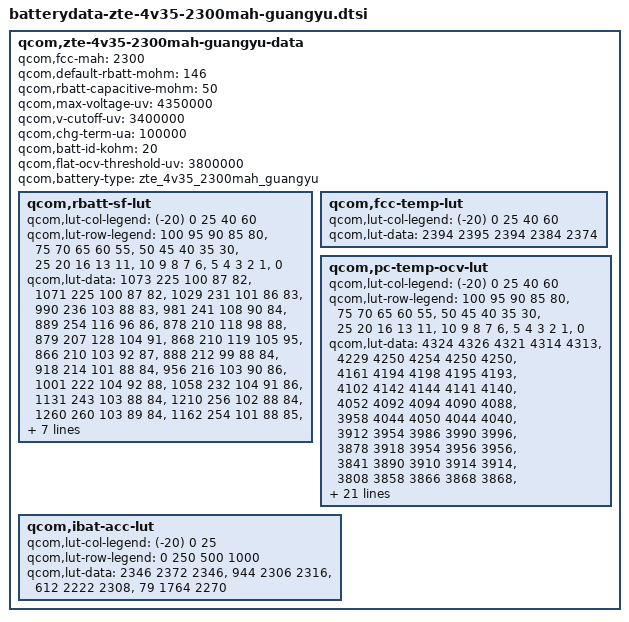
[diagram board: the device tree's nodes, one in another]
/* Copyright (c) 2014, The Linux Foundation. All rights reserved.
 *
 * This program is free software; you can redistribute it and/or modify
 * it under the terms of the GNU General Public License version 2 and
 * only version 2 as published by the Free Software Foundation.
 *
 * This program is distributed in the hope that it will be useful,
 * but WITHOUT ANY WARRANTY; without even the implied warranty of
 * MERCHANTABILITY or FITNESS FOR A PARTICULAR PURPOSE.  See the
 * GNU General Public License for more details.
 */
 qcom,zte-4v35-2300mah-guangyu-data {
	qcom,fcc-mah = <2300>;
	qcom,default-rbatt-mohm = <146>;
	qcom,rbatt-capacitive-mohm = <50>;
	qcom,max-voltage-uv = <4350000>;
	qcom,v-cutoff-uv = <3400000>;
	qcom,chg-term-ua = <100000>;
	qcom,batt-id-kohm = <20>;
	qcom,flat-ocv-threshold-uv = <3800000>;
	qcom,battery-type = "zte_4v35_2300mah_guangyu";

	qcom,rbatt-sf-lut {
		qcom,lut-col-legend = <(-20) 0 25 40 60>;
		qcom,lut-row-legend = <100 95 90 85 80>,
				<75 70 65 60 55>,
				<50 45 40 35 30>,
				<25 20 16 13 11>,
				<10 9 8 7 6>,
				<5 4 3 2 1>,
				<0>;
		qcom,lut-data = <1073 225 100 87 82>,
				<1071 225 100 87 82>,
				<1029 231 101 86 83>,
				<990 236 103 88 83>,
				<981 241 108 90 84>,
				<889 254 116 96 86>,
				<878 210 118 98 88>,
				<879 207 128 104 91>,
				<868 210 119 105 95>,
				<866 210 103 92 87>,
				<888 212 99 88 84>,
				<918 214 101 88 84>,
				<956 216 103 90 86>,
				<1001 222 104 92 88>,
				<1058 232 104 91 86>,
				<1131 243 103 88 84>,
				<1210 256 102 88 84>,
				<1260 260 103 89 84>,
				<1162 254 101 88 85>,
				<1230 270 103 89 85>,
				<1268 282 104 90 86>,
				<1308 295 105 91 86>,
				<1352 311 108 92 88>,
				<1399 327 111 94 88>,
				<1453 342 112 93 88>,
				<1520 349 109 91 86>,
				<1740 361 109 93 88>,
				<2118 397 114 96 89>,
				<2729 457 121 102 95>,
				<4560 559 161 136 125>,
				<105999 51373 46123 42008 26055>;
	};

	qcom,fcc-temp-lut {
		qcom,lut-col-legend = <(-20) 0 25 40 60>;
		qcom,lut-data = <2394 2395 2394 2384 2374>;
	};

	qcom,pc-temp-ocv-lut {
		qcom,lut-col-legend = <(-20) 0 25 40 60>;
		qcom,lut-row-legend = <100 95 90 85 80>,
				<75 70 65 60 55>,
				<50 45 40 35 30>,
				<25 20 16 13 11>,
				<10 9 8 7 6>,
				<5 4 3 2 1>,
				<0>;
		qcom,lut-data = <4324 4326 4321 4314 4313>,
				<4229 4250 4254 4250 4250>,
				<4161 4194 4198 4195 4193>,
				<4102 4142 4144 4141 4140>,
				<4052 4092 4094 4090 4088>,
				<3958 4044 4050 4044 4040>,
				<3912 3954 3986 3990 3996>,
				<3878 3918 3954 3956 3956>,
				<3841 3890 3910 3914 3914>,
				<3808 3858 3866 3868 3868>,
				<3788 3832 3838 3838 3837>,
				<3775 3809 3816 3816 3815>,
				<3764 3790 3798 3798 3796>,
				<3754 3778 3784 3783 3781>,
				<3744 3768 3770 3766 3760>,
				<3734 3758 3756 3747 3734>,
				<3722 3742 3739 3728 3714>,
				<3708 3722 3718 3707 3693>,
				<3696 3707 3696 3686 3672>,
				<3682 3700 3690 3682 3670>,
				<3675 3698 3689 3681 3669>,
				<3666 3694 3688 3680 3667>,
				<3654 3692 3686 3678 3665>,
				<3639 3688 3684 3674 3661>,
				<3620 3678 3674 3662 3645>,
				<3596 3656 3645 3628 3609>,
				<3565 3613 3600 3580 3560>,
				<3517 3554 3534 3516 3496>,
				<3446 3471 3449 3430 3410>,
				<3317 3340 3314 3294 3276>,
				<3000 3000 3000 3000 3014>;
	};
		qcom,ibat-acc-lut {
		qcom,lut-col-legend = <(-20) 0 25>;
		qcom,lut-row-legend = <0 250 500 1000>;
		qcom,lut-data = <2346 2372 2346>,
				<944 2306 2316>,
				<612 2222 2308>,
				<79 1764 2270>;
	};
};
